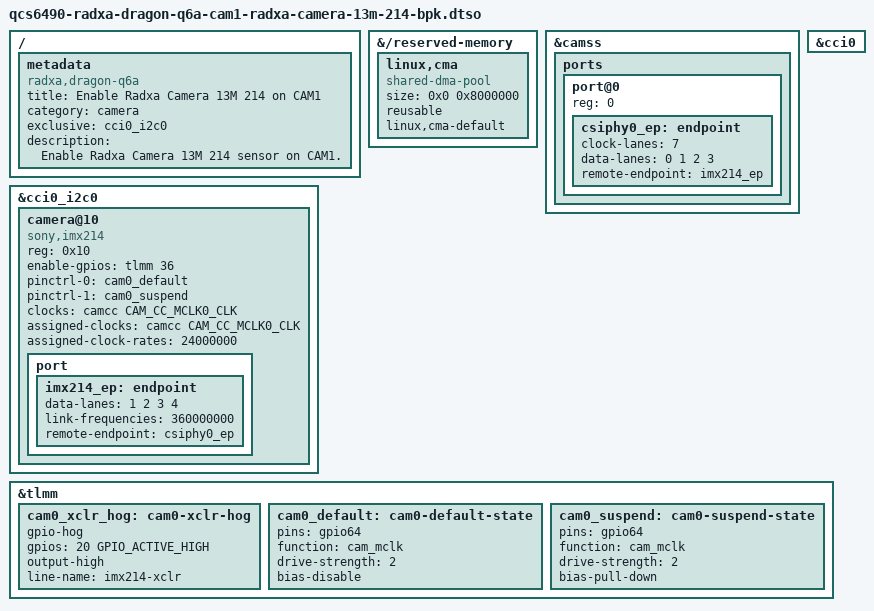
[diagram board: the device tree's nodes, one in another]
// SPDX-License-Identifier: BSD-3-Clause
/*
 * Copyright (c) 2025 Radxa Computer (Shenzhen) Co., Ltd.
 */

// Vendored from radxa-pkg/radxa-overlays @ a0ffd564a2fd with two changes:
//  1. The vdda-phy/vdda-pll supplies are dropped because the qcom-next 7.0 DT
//     for the Dragon Q6A does not define the PMIC regulators yet (the regulator
//     core hands the CAMSS driver dummies). The rails ride the PMIC power-on
//     defaults.
//  2. The sensor's reset-gpios (XCLR, gpio20) is replaced by a gpio-hog that
//     drives gpio20 high at boot. The upstream imx214 driver only claims
//     enable-gpios, so reset-gpios was left floating and held the sensor in
//     reset (I2C ENXIO on chip-id read). Verified on the bench board: with
//     gpio20 high the sensor probes and captures. See cam0_xclr_hog below.

/dts-v1/;
/plugin/;

#include <dt-bindings/clock/qcom,camcc-sc7280.h>
#include <dt-bindings/gpio/gpio.h>

/ {
	metadata {
		title = "Enable Radxa Camera 13M 214 on CAM1";
		compatible = "radxa,dragon-q6a";
		category = "camera";
		exclusive = "cci0_i2c0";
		description = "Enable Radxa Camera 13M 214 sensor on CAM1.";
	};
};

&{/reserved-memory} {
	linux,cma {
		compatible = "shared-dma-pool";
		size = <0x0 0x8000000>;
		reusable;
		linux,cma-default;
	};
};

&camss {

	status = "okay";

	ports {
		#address-cells = <1>;
		#size-cells = <0>;

		/* The port index denotes CSIPHY id i.e. csiphy0 */
		port@0 {
			reg = <0>;

			csiphy0_ep: endpoint {
				clock-lanes = <7>;
				data-lanes = <0 1 2 3>;
				remote-endpoint = <&imx214_ep>;
			};
		};
	};
};

&cci0 {
	status = "okay";
};

&cci0_i2c0 {
	#address-cells = <1>;
	#size-cells = <0>;

	camera@10 {
		compatible = "sony,imx214";

		reg = <0x10>;

		// XCLR (gpio20) is NOT listed as reset-gpios: the upstream imx214
		// driver only claims enable-gpios, so a reset-gpios here would be
		// left floating-input and hold the sensor in reset (I2C ENXIO on
		// chip-id read). XCLR is instead driven high by the cam0_xclr_hog
		// gpio-hog below. enable-gpios stays — the driver does use it.
		enable-gpios = <&tlmm 36 GPIO_ACTIVE_HIGH>;
		pinctrl-names = "default", "suspend";
		pinctrl-0 = <&cam0_default>;
		pinctrl-1 = <&cam0_suspend>;

		clocks = <&camcc CAM_CC_MCLK0_CLK>;
		assigned-clocks = <&camcc CAM_CC_MCLK0_CLK>;
		assigned-clock-rates = <24000000>;

		port {
			imx214_ep: endpoint {
				data-lanes = <1 2 3 4>;
				link-frequencies = /bits/ 64 <360000000>;
				remote-endpoint = <&csiphy0_ep>;
			};
		};
	};
};

&tlmm {
	// Drive IMX214 XCLR (gpio20, active-high reset release) high at gpiochip
	// registration and hold it. The imx214 driver ignores reset-gpios, so
	// without this the line floats and the sensor never leaves reset.
	cam0_xclr_hog: cam0-xclr-hog {
		gpio-hog;
		gpios = <20 GPIO_ACTIVE_HIGH>;
		output-high;
		line-name = "imx214-xclr";
	};

	cam0_default: cam0-default-state {
		pins = "gpio64";
		function = "cam_mclk";
		drive-strength = <2>;
		bias-disable;
	};

	cam0_suspend: cam0-suspend-state {
		pins = "gpio64";
		function = "cam_mclk";
		drive-strength = <2>;
		bias-pull-down;
	};
};
